# STM32U575 register map
File version: 1.4
CPU: CM33 r0p1, little endian, MPU, FPU, 4 interrupt priority bits
Registers are 32-bit, read-write, reset 0x0 unless marked. A register's access mark holds for its fields unless they carry their own. Offsets are from the block's base; [hi:lo] are bit positions; {n}, {i} and the like mark numbered series; 'fields as' and 'values as' point back to an identical list.

## EXTI — External interrupt/event controller
Base 0x46022000
Same registers: SEC_EXTI 0x56022000
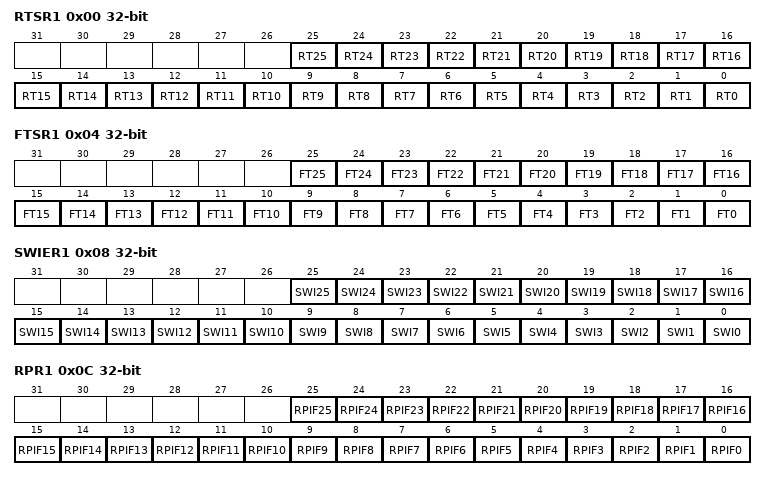
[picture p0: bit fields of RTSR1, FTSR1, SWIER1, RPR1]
0x00 RTSR1 — EXTI rising trigger selection register
  [all] fields
    0=Disabled (Rising edge trigger is disabled); 1=Enabled (Rising edge trigger is enabled)
  [n] RT{n} (n=0..25) — Rising trigger event configuration bit of configurable event input x When EXTI_SECCFGR.SECx is disabled, RTx can be accessed with non-secure and secure access. When EXTI_SECCFGR.SECx is enabled, RTx can only be accessed with secure access. Non-secure write to this bit x is discarded and non-secure read returns 0. When EXTI_PRIVCFGR.PRIVx is disabled, RTx can be accessed with unprivileged and privileged access. When EXTI_PRIVCFGR.PRIVx is enabled, RTx can only be accessed with privileged access. Unprivileged write to this bit x is discarded, unprivileged read returns 0. Note: RT25, RT24, and RT23 bits are only available on some devices in the STM32U5 Series. Refer to the EXTI line connections table for its availability. If not present, consider this bit as reserved and keep at reset value.
0x04 FTSR1 — EXTI falling trigger selection register
  [all] fields
    0=Disabled (Falling edge trigger is disabled); 1=Enabled (Falling edge trigger is enabled)
  [n] FT{n} (n=0..25) — Falling trigger event configuration bit of configurable event input x When EXTI_SECCFGR.SECx is disabled, FTx can be accessed with non-secure and secure access. When EXTI_SECCFGR.SECx is enabled, FTx can only be accessed with secure access. Non-secure write to this FTx is discarded, non-secure read returns 0. When EXTI_PRIVCFGR.PRIVx is disabled, FTx can be accessed with unprivileged and privileged access. When EXTI_PRIVCFGR.PRIVx is enabled, FTx can only be accessed with privileged access. Unprivileged write to this FTx is discarded, unprivileged read returns 0. Note: FT25, FT24, and FT23 bits are only available on some devices in the STM32U5 Series. Refer to the EXTI line connections table for its availability. If not present, consider this bit as reserved and keep at reset value.
0x08 SWIER1 — EXTI software interrupt event register
  [all] fields
    on write: 1=Pend (Generates an interrupt request)
  [n] SWI{n} (n=0..25) — Software interrupt on event x When EXTI_SECCFGR.SECx is disabled, SWIx can be accessed with non-secure and secure access. When EXTI_SECCFGR.SECx is enabled, SWIx can only be accessed with secure access. Non-secure write to this SWI x is discarded, non-secure read returns 0. When EXTI_PRIVCFGR.PRIVx is disabled, SWIx can be accessed with unprivileged and privileged access. When EXTI_PRIVCFGR.PRIVx is enabled, SWIx can only be accessed with privileged access. Unprivileged write to this SWIx is discarded, unprivileged read returns 0. A software interrupt is generated independent from the setting in EXTI_RTSR and EXTI_FTSR. It always returns 0 when read. Note: SW25, SW24, and SW23 bits are only available on some devices in the STM32U5 Series. Refer to the EXTI line connections table for its availability. If not present, consider this bit as reserved and keep at reset value.
0x0C RPR1 — EXTI rising edge pending register
  [all] fields
    on read: 0=NotPending (No trigger request occurred); 1=Pending (Selected trigger request occurred) | on write: 1=Clears pending bit
  [n] RPIF{n} write-1-clears (n=0..25) — configurable event inputs x rising edge pending bit When EXTI_SECCFGR.SECx is disabled, RPIFx can be accessed with non-secure and secure access. When EXTI_SECCFGR.SECx is enabled, RPIFx can only be accessed with secure access. Non-secure write to this RPIFx is discarded, non-secure read returns 0. When EXTI_PRIVCFGR.PRIVx is disabled, RPIFx can be accessed with unprivileged and privileged access. When EXTI_PRIVCFGR.PRIVx is enabled, RPIFx can only be accessed with privileged access. Unprivileged write to this RPIFx is discarded, unprivileged read returns 0. This bit is set when the rising edge event or an EXTI_SWIER software trigger arrives on the configurable event line. This bit is cleared by writing 1 to it. RPIF25, RPIF24, and RPIF23 bits are only available on some devices in the STM32U5 Series. Refer to the EXTI line connections table for its availability. Note: If not present, consider this bit as reserved and keep at reset value.
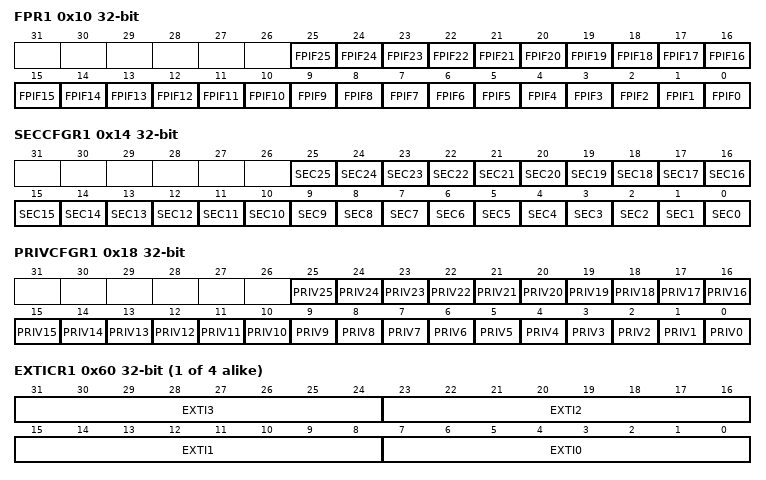
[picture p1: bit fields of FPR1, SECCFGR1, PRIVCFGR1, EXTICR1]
0x10 FPR1 — EXTI falling edge pending register
  [all] fields
    values as the fields of RPR1
  [n] FPIF{n} write-1-clears (n=0..25) — configurable event inputs x falling edge pending bit When EXTI_SECCFGR.SECx is disabled, FPIFx can be accessed with non-secure and secure access. When EXTI_SECCFGR.SECx is enabled, FPIFx can only be accessed with secure access. Non-secure write to this FPIFx is discarded, non-secure read returns 0. When EXTI_PRIVCFGR.PRIVx is disabled, FPIFx can be accessed with unprivileged and privileged access. When EXTI_PRIVCFGR.PRIVx is enabled, FPIFx can only be accessed with privileged access. Unprivileged write to this FPIFx is discarded, unprivileged read returns 0. This bit is set when the falling edge event arrives on the configurable event line. This bit is cleared by writing 1 to it. Note: FPIF25, FPIF24, and FPIF23 bits are only available on some devices in the STM32U5 Series. Refer to the EXTI line connections table for its availability. If not present, consider this bit as reserved and keep at reset value.
0x14 SECCFGR1 — EXTI security configuration register
  [n] SEC{n} (n=0..25) — Security enable on event input x When EXTI_PRIVCFGR.PRIVx is disabled, SECx can be accessed with privileged and unprivileged access. When EXTI_PRIVCFGR.PRIVx is enabled, SECx can only be written with privileged access. Unprivileged write to this SECx is discarded. Note: SEC25, SEC24, and SEC23 bits are only available on some devices in the STM32U5 Series. Refer to the EXTI line connections table for its availability. If not present, consider this bit as reserved and keep at reset value.
0x18 PRIVCFGR1 — EXTI privilege configuration register
  [all] fields
    0=Unprivileged (Event privilege disabled); 1=Privileged (Event privilege enabled)
  [n] PRIV{n} (n=0..25) — Security enable on event input x When EXTI_SECCFGR.SECx is disabled, PRIVx can be accessed with secure and non-secure access. When EXTI_SECCFGR.SECx is enabled, PRIVx can only be written with secure access. Non-secure write to this PRIVx is discarded. Note: PRIV25, PRIV24, and PRIV23 bits are only available on some devices in the STM32U5 Series. Refer to the EXTI line connections table for its availability. If not present, consider this bit as reserved and keep at reset value.
{0x5C+4i} EXTICR{i} (i=1..4) — EXTI external interrupt selection register
  [all] fields
    0=PA (Select PAx as the source input for the EXTIx external interrupt); 1=PB (Select PBx as the source input for the EXTIx external interrupt); 2=PC (Select PCx as the source input for the EXTIx external interrupt); 3=PD (Select PDx as the source input for the EXTIx external interrupt); 4=PE (Select PEx as the source input for the EXTIx external interrupt); 5=PF (Select PFx as the source input for the EXTIx external interrupt); 6=PG (Select PGx as the source input for the EXTIx external interrupt); 7=PH (Select PHx as the source input for the EXTIx external interrupt); 8=PI (Select PIx as the source input for the EXTIx external interrupt); 9=PJ (Select PJx as the source input for the EXTIx external interrupt)
  [31:24] EXTI{4i-1} — EXTIm+3 GPIO port selection
  [23:16] EXTI{4i-2} — EXTIm+2 GPIO port selection
  [15:8] EXTI{4i-3} — EXTIm+1 GPIO port selection
  [7:0] EXTI{4i-4} — EXTIm GPIO port selection
0x70 LOCKR — EXTI lock register
  [0] LOCK — Global security and privilege configuration registers (EXTI_SECCFGR and EXTI_PRIVCFGR) lock This bit is written once after reset.
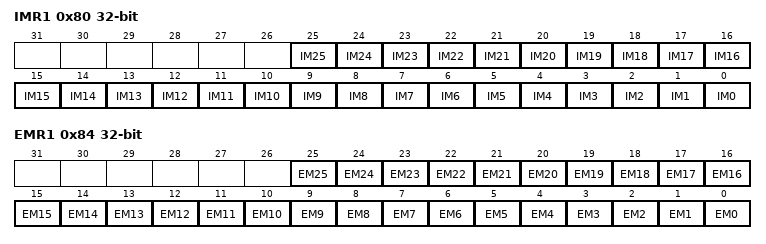
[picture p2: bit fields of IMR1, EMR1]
0x80 IMR1 — EXTI CPU wake-up with interrupt mask register
  [all] fields
    0=Masked (Interrupt request line is masked); 1=Unmasked (Interrupt request line is unmasked)
  [n] IM{n} (n=0..25) — CPU wake-up with interrupt mask on event input x When EXTI_SECCFGR.SECx is disabled, IMx can be accessed with non-secure and secure access. When EXTI_SECCFGR.SECx is enabled, IMx can only be accessed with secure access. Non-secure write to this bit is discarded and non-secure read returns 0. When EXTI_PRIVCFGR.PRIVx is disabled, IMx can be accessed with privileged and unprivileged access. When EXTI_PRIVCFGR.PRIVx is enabled, IMx can only be accessed with privileged access. Unprivileged write to this bit is discarded. Note: IM25, IM24, and IM23 bits are only available on some devices in the STM32U5 Series. Refer to the EXTI line connections table for its availability. If not present, consider this bit as reserved and keep at reset value.
0x84 EMR1 — EXTI CPU wake-up with event mask register
  [all] fields
    0=Masked (Event request line is masked); 1=Unmasked (Event request line is unmasked)
  [n] EM{n} (n=0..25) — CPU wake-up with event generation mask on event input x When EXTI_SECCFGR.SECx is disabled, EMx can be accessed with non-secure and secure access. When EXTI_SECCFGR.SECx is enabled, EMx can only be accessed with secure access. Non-secure write to this bit x is discarded and non-secure read returns 0. When EXTI_PRIVCFGR.PRIVx is disabled, EMx can be accessed with privileged and unprivileged access. When EXTI_PRIVCFGR.PRIVx is enabled, EMx can only be accessed with privileged access. Unprivileged write to this bit is discarded. Note: EM25, EM24, and EM23 bits are only available on some devices in the STM32U5 Series. Refer to the EXTI line connections table for its availability. If not present, consider this bit as reserved and keep at reset value.
